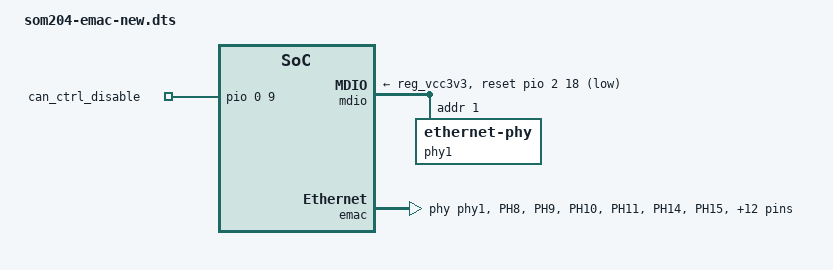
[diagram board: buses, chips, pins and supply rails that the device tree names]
/dts-v1/;
/plugin/;

/ {
	compatible = "olimex,a20-olimex-som204-evb",
		     "olimex,a20-olimex-som204-evb-emmc";
	description = "Enable 100M EMAC2 (disable GMAC + disable CAN + CAN_CTRL high)";

	/* Disable GMAC */
	fragment@0 {
		target = <&gmac>;
		__overlay__ {
			status = "disabled";
		};
	};

	/* EMAC2 pinmux (includes PH20/PH21 => conflicts with CAN) */
	fragment@1 {
		target = <&pio>;
		__overlay__ {
			emac_pins_b: emac0@1 {
				pins = "PH8", "PH9", "PH10", "PH11",
				       "PH14", "PH15", "PH16", "PH17",
				       "PH18", "PH19", "PH20", "PH21",
				       "PH22", "PH23", "PH24", "PH25",
				       "PH26", "PH27";
				function = "emac";
			};
		};
	};

	/* NEW: Drive PA9 high using gpio-leds (safe, no gpiochip failure) */
	fragment@2 {
		target-path = "/";
		__overlay__ {
			can_ctrl_lines: can-ctrl-lines {
				compatible = "gpio-leds";

				/* PA9 физически HIGH => CAN драйвер disable */
				can_ctrl_disable: can_ctrl_disable {
					label = "can_ctrl_disable";
					gpios = <&pio 0 9 0>;      /* 0 = ACTIVE_HIGH */
					default-state = "on";     /* => HIGH */
				};
			};
		};
	};

	/* MDIO + PHY on EMAC2, PC18 reset line */
	fragment@3 {
		target = <&mdio>;
		__overlay__ {
			phy-supply = <&reg_vcc3v3>;
			/* 1 = ACTIVE_LOW (reset#) */
			reset-gpios = <&pio 2 18 1>; /* PC18 MEPHY-RST# */
			status = "okay";

			phy1: ethernet-phy@1 {
				reg = <1>;
			};
		};
	};

	/* Enable EMAC2 */
	fragment@4 {
		target = <&emac>;
		__overlay__ {
			pinctrl-names = "default";
			pinctrl-0 = <&emac_pins_b>;
			phy = <&phy1>;
			status = "okay";
		};
	};

	fragment@5 {
		target = <&emac_sram>;
		__overlay__ {
			status = "okay";
		};
	};

	/* Disable CAN controller so it releases PH20/PH21 */
	fragment@6 {
		target = <&can0>;
		__overlay__ {
			status = "disabled";
		};
	};
};

